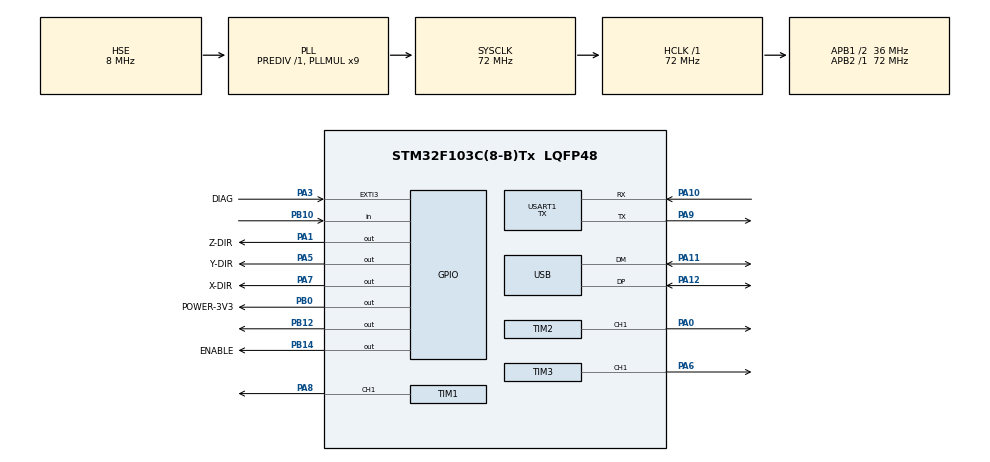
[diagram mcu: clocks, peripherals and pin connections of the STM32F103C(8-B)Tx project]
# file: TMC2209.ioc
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Mcu.Family=STM32F1
Mcu.Name=STM32F103C(8-B)Tx
Mcu.Package=LQFP48
NVIC.EXTI3_IRQn=true\:0\:0\:false\:false\:true\:true\:true\:true
NVIC.PriorityGroup=NVIC_PRIORITYGROUP_4
NVIC.TIM1_UP_IRQn=true\:0\:0\:false\:false\:true\:true\:true\:true
NVIC.TIM2_IRQn=true\:0\:0\:false\:false\:true\:true\:true\:true
NVIC.TIM3_IRQn=true\:0\:0\:false\:false\:true\:true\:true\:true
NVIC.USART1_IRQn=true\:0\:0\:false\:false\:true\:true\:true\:true
NVIC.USB_HP_CAN1_TX_IRQn=true\:0\:0\:false\:false\:true\:true\:true\:true
NVIC.USB_LP_CAN1_RX0_IRQn=true\:0\:0\:false\:false\:true\:false\:true\:true
PA0-WKUP.Signal=S_TIM2_CH1_ETR
PA1.GPIO_Label=Z-DIR
PA1.GPIO_Speed=GPIO_SPEED_FREQ_HIGH
PA1.Signal=GPIO_Output
PA10.Mode=Asynchronous
PA10.Signal=USART1_RX
PA11.Mode=Device
PA11.Signal=USB_DM
PA12.Mode=Device
PA12.Signal=USB_DP
PA13.Mode=Serial_Wire
PA13.Signal=SYS_JTMS-SWDIO
PA14.Mode=Serial_Wire
PA14.Signal=SYS_JTCK-SWCLK
PA3.GPIO_Label=DIAG
PA3.Signal=GPXTI3
PA5.GPIO_Label=Y-DIR
PA5.GPIO_Speed=GPIO_SPEED_FREQ_HIGH
PA5.Signal=GPIO_Output
PA6.Signal=S_TIM3_CH1
PA7.GPIO_Label=X-DIR
PA7.GPIO_Speed=GPIO_SPEED_FREQ_HIGH
PA7.Signal=GPIO_Output
PA8.Signal=S_TIM1_CH1
PA9.Mode=Asynchronous
PA9.Signal=USART1_TX
PB0.GPIO_Label=POWER-3V3
PB0.Signal=GPIO_Output
PB10.GPIO_PuPd=GPIO_PULLDOWN
PB10.Signal=GPIO_Input
PB12.GPIO_Speed=GPIO_SPEED_FREQ_HIGH
PB12.PinState=GPIO_PIN_SET
PB12.Signal=GPIO_Output
PB14.GPIO_Label=ENABLE
PB14.GPIO_Speed=GPIO_SPEED_FREQ_HIGH
PB14.PinState=GPIO_PIN_SET
PB14.Signal=GPIO_Output
PD0-OSC_IN.Mode=HSE-External-Oscillator
PD0-OSC_IN.Signal=RCC_OSC_IN
PD1-OSC_OUT.Mode=HSE-External-Oscillator
PD1-OSC_OUT.Signal=RCC_OSC_OUT
ProjectManager.HeapSize=0x200
ProjectManager.StackSize=0x400
ProjectManager.TargetToolchain=MDK-ARM V5.32
RCC.AHBFreq_Value=72000000
RCC.APB1CLKDivider=RCC_HCLK_DIV2
RCC.APB1Freq_Value=36000000
RCC.APB1TimFreq_Value=72000000
RCC.APB2Freq_Value=72000000
RCC.APB2TimFreq_Value=72000000
RCC.HCLKFreq_Value=72000000
RCC.PLLMUL=RCC_PLL_MUL9
RCC.PLLSourceVirtual=RCC_PLLSOURCE_HSE
RCC.SYSCLKFreq_VALUE=72000000
RCC.SYSCLKSource=RCC_SYSCLKSOURCE_PLLCLK
RCC.USBFreq_Value=48000000
RCC.USBPrescaler=RCC_USBCLKSOURCE_PLL_DIV1_5
SH.S_TIM1_CH1.0=TIM1_CH1,PWM Generation1 CH1
SH.S_TIM2_CH1_ETR.0=TIM2_CH1,PWM Generation1 CH1
SH.S_TIM3_CH1.0=TIM3_CH1,PWM Generation1 CH1
TIM1.AutoReloadPreload=TIM_AUTORELOAD_PRELOAD_ENABLE
TIM1.Channel-PWM\ Generation1\ CH1=TIM_CHANNEL_1
TIM1.OCFastMode_PWM-PWM\ Generation1\ CH1=TIM_OCFAST_ENABLE
TIM1.Period=299
TIM2.AutoReloadPreload=TIM_AUTORELOAD_PRELOAD_ENABLE
TIM2.Channel-PWM\ Generation1\ CH1=TIM_CHANNEL_1
TIM2.Period=299
TIM2.Prescaler=71
TIM3.AutoReloadPreload=TIM_AUTORELOAD_PRELOAD_ENABLE
TIM3.Channel-PWM\ Generation1\ CH1=TIM_CHANNEL_1
TIM3.OCFastMode_PWM-PWM\ Generation1\ CH1=TIM_OCFAST_ENABLE
TIM3.Period=299
TIM3.Prescaler=72
USART1.Mode=MODE_TX
USART1.VirtualMode=VM_ASYNC
USB_DEVICE.CLASS_NAME_FS=CDC
USB_DEVICE.VirtualMode=Cdc
USB_DEVICE.VirtualModeFS=Cdc_FS
VP_TIM1_VS_ClockSourceINT.Mode=Internal
VP_TIM2_VS_ClockSourceINT.Mode=Internal
VP_TIM3_VS_ClockSourceINT.Mode=Internal
VP_USB_DEVICE_VS_USB_DEVICE_CDC_FS.Mode=CDC_FS
board=custom

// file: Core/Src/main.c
/* USER CODE BEGIN Header */
/**
  ******************************************************************************
  * @file           : main.c
  * @brief          : Main program body
  ******************************************************************************
  * @attention
  *
  * Copyright (c) 2026 STMicroelectronics.
  * All rights reserved.
  *
  * This software is licensed under terms that can be found in the LICENSE file
  * in the root directory of this software component.
  * If no LICENSE file comes with this software, it is provided AS-IS.
  *
  ******************************************************************************
  */
/* USER CODE END Header */
#include "main.h"
#include "tim.h"
#include "usart.h"
#include "usb_device.h"
#include "gpio.h"
#include "USB_Command.h"
#include "usbd_cdc.h"
#include "PUL.h"

void SystemClock_Config(void);

/* USER CODE BEGIN 0 */
extern USBD_HandleTypeDef hUsbDeviceFS;
/* USER CODE END 0 */

int main(void)
{

  /* MCU Configuration--------------------------------------------------------*/

  /* Reset of all peripherals, Initializes the Flash interface and the Systick. */
  HAL_Init();

  /* Configure the system clock */
  SystemClock_Config();

  /* Initialize all configured peripherals */
  MX_GPIO_Init();
  MX_USB_DEVICE_Init();
  MX_TIM1_Init();
  MX_TIM2_Init();
  MX_TIM3_Init();
  MX_USART1_UART_Init();
  /* USER CODE BEGIN 2 */
  PUL_Init();
  USB_Command_Init();
  /* USER CODE END 2 */

  /* Infinite loop */
  while (1)
  {

    /* USER CODE BEGIN 3 */
	Motor_Update();
	USB_Command_Update();
  }
  /* USER CODE END 3 */
}

void SystemClock_Config(void)
{
  RCC_OscInitTypeDef RCC_OscInitStruct = {0};
  RCC_ClkInitTypeDef RCC_ClkInitStruct = {0};
  RCC_PeriphCLKInitTypeDef PeriphClkInit = {0};

  /** Initializes the RCC Oscillators according to the specified parameters
  * in the RCC_OscInitTypeDef structure.
  */
  RCC_OscInitStruct.OscillatorType = RCC_OSCILLATORTYPE_HSE;
  RCC_OscInitStruct.HSEState = RCC_HSE_ON;
  RCC_OscInitStruct.HSEPredivValue = RCC_HSE_PREDIV_DIV1;
  RCC_OscInitStruct.HSIState = RCC_HSI_ON;
  RCC_OscInitStruct.PLL.PLLState = RCC_PLL_ON;
  RCC_OscInitStruct.PLL.PLLSource = RCC_PLLSOURCE_HSE;
  RCC_OscInitStruct.PLL.PLLMUL = RCC_PLL_MUL9;
  if (HAL_RCC_OscConfig(&RCC_OscInitStruct) != HAL_OK)
  {
    Error_Handler();
  }

  /** Initializes the CPU, AHB and APB buses clocks
  */
  RCC_ClkInitStruct.ClockType = RCC_CLOCKTYPE_HCLK|RCC_CLOCKTYPE_SYSCLK
                              |RCC_CLOCKTYPE_PCLK1|RCC_CLOCKTYPE_PCLK2;
  RCC_ClkInitStruct.SYSCLKSource = RCC_SYSCLKSOURCE_PLLCLK;
  RCC_ClkInitStruct.AHBCLKDivider = RCC_SYSCLK_DIV1;
  RCC_ClkInitStruct.APB1CLKDivider = RCC_HCLK_DIV2;
  RCC_ClkInitStruct.APB2CLKDivider = RCC_HCLK_DIV1;

  if (HAL_RCC_ClockConfig(&RCC_ClkInitStruct, FLASH_LATENCY_2) != HAL_OK)
  {
    Error_Handler();
  }
  PeriphClkInit.PeriphClockSelection = RCC_PERIPHCLK_USB;
  PeriphClkInit.UsbClockSelection = RCC_USBCLKSOURCE_PLL_DIV1_5;
  if (HAL_RCCEx_PeriphCLKConfig(&PeriphClkInit) != HAL_OK)
  {
    Error_Handler();
  }
}

void Error_Handler(void)
{
  __disable_irq();
  while (1)
  {
  }
}
